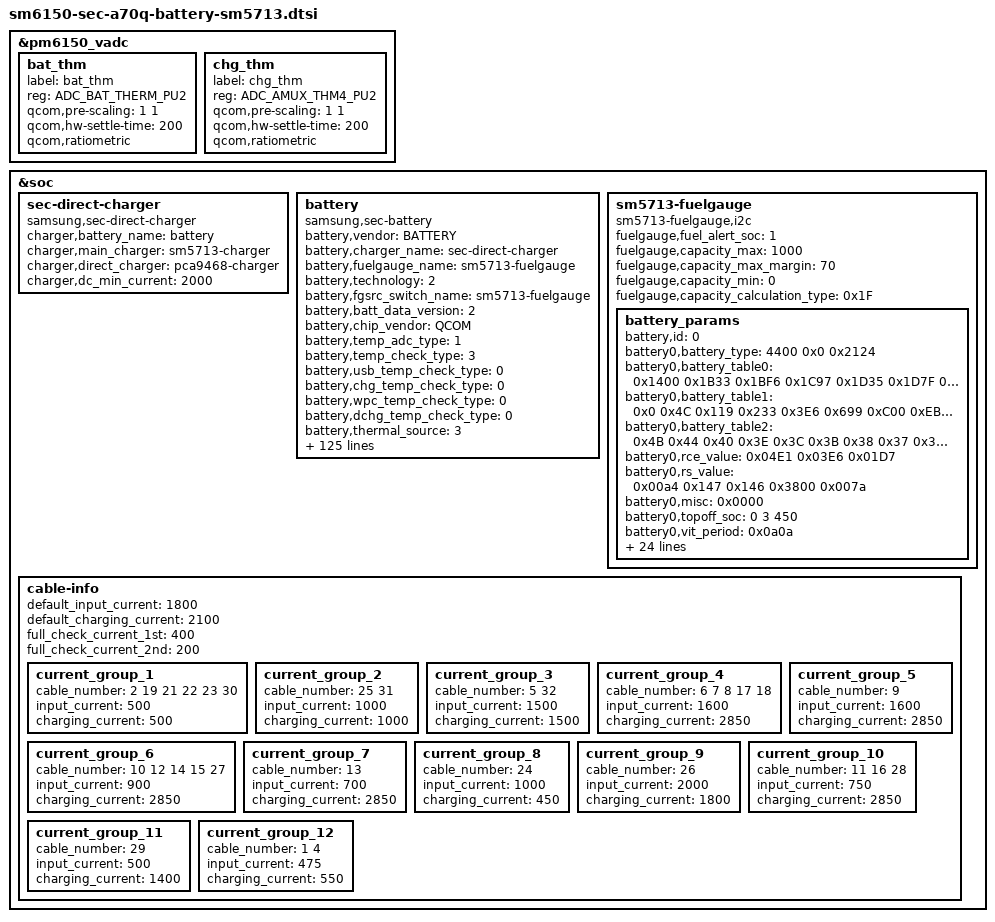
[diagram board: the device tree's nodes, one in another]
/* Copyright (c) 2014, The Linux Foundation. All rights reserved.
 *
 * This program is free software; you can redistribute it and/or modify
 * it under the terms of the GNU General Public License version 2 and
 * only version 2 as published by the Free Software Foundation.
 *
 * This program is distributed in the hope that it will be useful,
 * but WITHOUT ANY WARRANTY; without even the implied warranty of
 * MERCHANTABILITY or FITNESS FOR A PARTICULAR PURPOSE.  See the
 * GNU General Public License for more details.
 */

&pm6150_vadc {
	bat_thm { /* BAT_THERM */
		label = "bat_thm";
		reg = <ADC_BAT_THERM_PU2>;
		qcom,pre-scaling = <1 1>;
		qcom,hw-settle-time = <200>;
		qcom,ratiometric;
	};
	chg_thm { /* AMUX_4 */
		label = "chg_thm";
		reg = <ADC_AMUX_THM4_PU2>;
		qcom,pre-scaling = <1 1>;
		qcom,hw-settle-time = <200>;
		qcom,ratiometric;
	};
};

&soc {
	sec-direct-charger {
		status = "okay";
		compatible = "samsung,sec-direct-charger";

		charger,battery_name = "battery";
		charger,main_charger = "sm5713-charger";
		charger,direct_charger = "pca9468-charger";

		charger,dc_min_current = <2000>;
	};

	battery {
		status = "okay";
		compatible = "samsung,sec-battery";
		pinctrl-names = "default";
		battery,vendor = "BATTERY";
		battery,charger_name = "sec-direct-charger";
		battery,fuelgauge_name = "sm5713-fuelgauge";
		battery,technology = <2>; /* POWER_SUPPLY_TECHNOLOGY_LION */
		battery,fgsrc_switch_name = "sm5713-fuelgauge"; /* Fuelgauge voltage source */

		battery,batt_data_version = <2>;

		battery,chip_vendor = "QCOM";
		battery,temp_adc_type = <1>; /* SEC_BATTERY_ADC_TYPE_AP */

		battery,temp_check_type = <3>; /* SEC_BATTERY_TEMP_CHECK_ADC */
		battery,usb_temp_check_type = <0>;
		battery,chg_temp_check_type = <0>;
		battery,wpc_temp_check_type = <0>;
		battery,dchg_temp_check_type = <0>; /* SEC_BATTERY_TEMP_CHECK_NONE for test */

		battery,thermal_source = <3>; /* SEC_BATTERY_THERMAL_SOURCE_ADC */
		battery,usb_thermal_source = <0>; /* SEC_BATTERY_THERMAL_SOURCE_NONE */
		battery,chg_thermal_source = <3>; /* SEC_BATTERY_THERMAL_SOURCE_ADC */
		battery,wpc_thermal_source = <0>; /* SEC_BATTERY_THERMAL_SOURCE_NONE */
		battery,dchg_thermal_source = <3>; /* SEC_BATTERY_THERMAL_SOURCE_CHG_ADC */

		battery,polling_time = <10 30 30 30 3600>;

		battery,temp_table_adc = <121128 144571 172663 209017 245998
						291586 341283 402659 472728 547188
						629714 693750 796993 896626 1005211
						1117430 1217992 1321993 1417603 1502075
						1573766 1637781 1684580>;
		battery,temp_table_data = <900 850 800 750 700
						650 600 550 500 450
						400 350 300 250 200
						150 100 50 0 (-50)
						(-100) (-150) (-200)>;

		battery,chg_temp_table_adc = <118209 142495 170328 206617 244204
						289727 339532 401340 471755 547123
						627421 691586 794744 894246 1003135
						1115419 1215484 1319225 1415419 1499740
						1569095 1638126 1685639>;
		battery,chg_temp_table_data = <900 850 800 750 700
						650 600 550 500 450
						400 350 300 250 200
						150 100 50 0 (-50)
						(-100) (-150) (-200)>;

		battery,dchg_temp_table_adc = <110882 138414 166566 194718 234600
						276828 326094 387090 448086 525504
						607614 696762 792948 893826 999396
						1107312 1210536 1304376 1393524 1473288
						1543668 1602318 1651584>;
		battery,dchg_temp_table_data = <900 850 800 750 700
						650 600 550 500 450
						400 350 300 250 200
						150 100 50 0 (-50)
						(-100) (-150) (-200)>;

		battery,adc_check_count = <5>;

		battery,cable_check_type = <4>; /* SEC_BATTERY_CABLE_CHECK_PSY */
		battery,cable_source_type = <1>; /* SEC_BATTERY_CABLE_SOURCE_EXTERNAL */
		battery,polling_type = <1>; /* SEC_BATTERY_MONITOR_ALARM */
		battery,monitor_initial_count = <0>;

		battery,battery_check_type = <0>; /* SEC_BATTERY_CHECK_NONE */
		battery,check_count = <0>;
		battery,check_adc_max = <1440>;
		battery,check_adc_min = <0>;

		battery,ovp_uvlo_check_type = <3>; /* SEC_BATTERY_OVP_UVLO_CHGPOLLING */

		battery,temp_check_count = <1>;
		battery,temp_highlimit_threshold_event = <800>;
		battery,temp_highlimit_recovery_event = <750>;
		battery,temp_high_threshold_event = <500>;
		battery,temp_high_recovery_event = <450>;
		battery,temp_low_threshold_event = <0>;
		battery,temp_low_recovery_event = <50>;
		battery,temp_highlimit_threshold_normal = <800>;
		battery,temp_highlimit_recovery_normal = <750>;
		battery,temp_high_threshold_normal = <500>;
		battery,temp_high_recovery_normal = <450>;
		battery,temp_low_threshold_normal = <0>;
		battery,temp_low_recovery_normal = <50>;
		battery,temp_highlimit_threshold_lpm = <800>;
		battery,temp_highlimit_recovery_lpm = <750>;
		battery,temp_high_threshold_lpm = <500>;
		battery,temp_high_recovery_lpm = <450>;
		battery,temp_low_threshold_lpm = <0>;
		battery,temp_low_recovery_lpm = <50>;
		
		battery,full_check_type = <2>; /* SEC_BATTERY_FULLCHARGED_FG_CURRENT */
		battery,full_check_type_2nd = <2>; /* SEC_BATTERY_FULLCHARGED_FG_CURRENT */
		battery,full_check_count = <1>;
		battery,chg_gpio_full_check = <0>;
		battery,chg_polarity_full_check = <1>;

		battery,chg_high_temp = <460>;
		battery,chg_high_temp_recovery = <440>;
		battery,chg_input_limit_current = <1000>;
		battery,chg_charging_limit_current = <1250>;
		battery,dchg_input_limit_current = <1000>;
		battery,dchg_charging_limit_current = <2000>;

		battery,mix_high_temp = <420>;
		battery,mix_high_chg_temp = <500>;
		battery,mix_high_temp_recovery = <390>;

		/* SEC_BATTERY_FULL_CONDITION_NOTIMEFULL | SEC_BATTERY_FULL_CONDITION_VCELL */
		battery,full_condition_type = <9>;
		battery,full_condition_soc = <93>;
		battery,full_condition_vcell = <4250>;

		battery,recharge_check_count = <1>;
		battery,recharge_condition_type = <4>; /* SEC_BATTERY_RECHARGE_CONDITION_VCELL */
		battery,recharge_condition_soc = <98>;
		battery,recharge_condition_vcell = <4280>;

		battery,charging_total_time = <14400>;
		battery,hv_charging_total_time = <10800>;
		battery,normal_charging_total_time = <18000>;
		battery,usb_charging_total_time = <36000>;
		battery,recharging_total_time = <5400>;
		battery,charging_reset_time = <0>;

		battery,chg_float_voltage = <4350>;

		battery,pre_afc_work_delay = <2000>;
		battery,pre_wc_afc_work_delay = <4000>;
		battery,pre_afc_input_current = <500>;
		battery,pre_wc_afc_input_current = <500>;
		battery,prepare_ta_delay = <0>; /* msec */

		battery,swelling_high_temp_block = <410>;
		battery,swelling_high_temp_recov = <390>;
		battery,swelling_low_temp_block_1st = <150>;
		battery,swelling_low_temp_recov_1st = <200>;
		battery,swelling_low_temp_block_2nd = <50>;
		battery,swelling_low_temp_recov_2nd = <100>;

		battery,swelling_low_temp_current = <950>;	/* 0.3C */
		battery,swelling_low_temp_current_2nd = <400>;	/* 0.1C */
		battery,swelling_low_temp_topoff = <200>;	/* 0.05C */
		battery,swelling_high_temp_current = <1400>;	/* 0.45C */
		battery,swelling_high_temp_topoff = <200>;	/* 0.05C */
		battery,swelling_wc_high_temp_current = <1400>;	/* 0.3C */
		battery,swelling_wc_low_temp_current = <950>;	/* 0.3C */
		battery,swelling_wc_low_temp_current_2nd = <400>;	/* 0.1C */

		battery,swelling_drop_float_voltage = <4150>;
		battery,swelling_high_rechg_voltage = <4000>;
		battery,swelling_low_rechg_voltage = <4000>;

		battery,siop_event_check_type = <1>;
		battery,siop_call_cv_current = <330>;
		battery,siop_call_cc_current = <330>;

		battery,siop_input_limit_current = <1200>;
		battery,siop_charging_limit_current = <1000>;
		battery,siop_hv_input_limit_current = <500>;
		battery,siop_hv_charging_limit_current = <1000>;

		battery,pd_charging_charge_power = <25000>;
		battery,max_charging_current = <5100>;

		/* cycle, chg_float_voltage, recharge_condition_vcell, full_condition_vcell, full_condition_soc */
		battery,age_data = <0 4350 4280 4250 93
				300 4330 4260 4230 92
				400 4310 4240 4210 91
				700 4290 4220 4190 90
				1000 4240 4170 4140 89>;

		/* step charging option */
		battery,step_charging_type = <0x61>; /* STEP_CHARGING_CONDITION_INPUT_CURRENT, CURRENT_NOW, FLOAT_VOLTAGE, VOLTAGE */
		battery,step_charging_charge_power = <15000>;
		battery,step_charging_condtion = <2000 1570 0>;
		battery,step_charging_soc_condtion = <40 70 100>;
		battery,step_charging_current = <4500 3950 3150>;
		battery,step_charging_float_voltage = <4090 4220 4350>;

		battery,max_input_voltage = <9000>; /* mV */
		battery,max_input_current = <3000>;  /* mA */

		battery,enable_sysovlo_irq;

		battery,standard_curr = <2850>;
		battery,expired_time = <10800>;
		battery,recharging_expired_time = <5400>;

		battery,battery_full_capacity = <4000>;
		battery,cisd_max_voltage_thr = <4400>; /* batttery ovp dettection voltage */
		battery,cisd_alg_index = <7>;

		io-channels = <&pm6150_vadc ADC_BAT_THERM_PU2>, <&pm6150_vadc ADC_AMUX_THM4_PU2>;
		io-channel-names = "adc-temp", "adc-chg-temp";
	};

	sm5713-fuelgauge{
			status = "okay";
			compatible = "sm5713-fuelgauge,i2c";
			fuelgauge,fuel_alert_soc = <1>;
			fuelgauge,capacity_max = <1000>;
			fuelgauge,capacity_max_margin = <70>;
			fuelgauge,capacity_min = <0>;
			fuelgauge,capacity_calculation_type = <0x1F>;
			battery_params {
				battery,id = <0>;
				battery0,battery_type = <4400 0x0 0x2124>; /* 4200 or 4350 or 4400 */
				battery0,battery_table0 = <0x1400 0x1B33 0x1BF6 0x1C97 0x1D35 0x1D7F 0x1D92 0x1DBA 0x1DF2 0x1E38 0x1E68 0x1EA0 0x1ED6 0x1F03 0x1F49 0x1F71 0x1FB7 0x1FC6 0x1FE9 0x202D 0x2086 0x20D1 0x2209 0x2400>;
				battery0,battery_table1 = <0x0 0x4C 0x119 0x233 0x3E6 0x699 0xC00 0xEB3 0x1433 0x1F00 0x29E6 0x3200 0x3780 0x3A33 0x3CE6 0x3F99 0x4500 0x47CC 0x4A80 0x4D33 0x4FE6 0x554C 0x6400 0x6419>;
				battery0,battery_table2 = <0x4B 0x44 0x40 0x3E 0x3C 0x3B 0x38 0x37 0x35 0x34 0x34 0x33 0x33 0x33 0x33 0x32>;
				battery0,rce_value = <0x04E1 0x03E6 0x01D7>;
				battery0,rs_value = <0x00a4 0x147 0x146 0x3800 0x007a>; /*rs p_mix_factor, n_mix_factor max min*/
				battery0,misc = <0x0000>;
				battery0,topoff_soc = <0 3 450>; /*disable soc*/
				battery0,vit_period = <0x0a0a>;
				battery0,dtcd_value = <0x1>;
				battery0,volt_cal = <0x800b 0x800b>;
				battery0,curr_offset = <1 0 0 0 0 0 0>;
				battery0,mix_value = <0x0103 0x0004>; /*mix_rate init_blank*/
				battery0,temp_std = <25>;
				battery0,temp_cal = <0 6 1 11 (-1) 1 6 1 9 1>;
				battery0,ext_temp_cal = <0 2 1 2 1 1 2 3 2 3>;
				battery0,temp_volcal = <1 15 1>;
				battery0,temp_offset = <1 11 1 1 8 (-1)>;
				battery0,curr_cal = <0x8080 0x8080 0x8080 0x8080 0x8080 0x8080>;
				battery0,tem_poff = <3400 50 3250 50>;
				battery0,arsm = <1 3 1 0x6>;
				battery0,cycle_cfg = <0 0 0>;
				battery0,full_offset = <0 50 0 0xD1 0x90>;
				battery0,age_cntl = <0x325>;
				battery0,tcal_ioff = <0x02 0x00>;
				battery0,v_offset_cancel = <0 0 100 10>;
				battery0,v_alarm = <3100 0>;
				battery0,v_max_table = <0x2209 0x2200 0x21ED 0x21CB 0x2175>;
				battery0,q_max_table = <0x2124 0x1CC4 0x1C44 0x1BC4 0x1A85>;
				battery0,data_ver = <1>;
			};
		};

/* sec_battery_cable
 *   0	UNKNOWN,
 *   1	NONE,
 *   2	PREPARE_TA,
 *   3	TA,
 *   4	USB,
 *   5	USB_CDP,
 *   6	9V_TA,
 *   7	9V_ERR,
 *   8	9V_UNKNOWN,
 *   9	12V_TA,
 *  10	WIRELESS,
 *  11	HV_WIRELESS,
 *  12	PMA_WIRELESS,
 *  13	WIRELESS_PACK,
 *  14	WIRELESS_PACK_TA,
 *  15	WIRELESS_STAND,
 *  16	WIRELESS_HV_STAND,
 *  17	QC20,
 *  18	QC30,
 *  19	PDIC,
 *  20	UARTOFF,
 *  21	OTG,
 *  22	LAN_HUB,
 *  23	POWER_SHARING,
 *  24	HMT_CONNECTED,
 *  25	HMT_CHARGE,
 *  26	HV_TA_CHG_LIMIT,
 *  27	WIRELESS_VEHICLE,
 *  28	WIRELESS_HV_VEHICLE,
 *  29	PREPARE_WIRELESS_HV,
 *  30	TIMEOUT,
 *  31	SMART_OTG,
 *  32	SMART_NOTG,
 *  33	PDIC_PPS,
 *  34	CABLE_MAX,
*/
	cable-info {
		default_input_current = <1800>;
		default_charging_current = <2100>;
		full_check_current_1st = <400>;
		full_check_current_2nd = <200>;

		current_group_1 {
			cable_number = <2 19 21 22 23 30>;
			input_current = <500>;
			charging_current = <500>;
		};
		current_group_2 {
			cable_number = <25 31>;
			input_current = <1000>;
			charging_current = <1000>;
		};
		current_group_3 {
			cable_number = <5 32>;
			input_current = <1500>;
			charging_current = <1500>;
		};
		current_group_4 {
			cable_number = <6 7 8 17 18>;
			input_current = <1600>;
			charging_current = <2850>;
		};
		current_group_5 {
			cable_number = <9>;
			input_current = <1600>;
			charging_current = <2850>;
		};
		current_group_6 {
			cable_number = <10 12 14 15 27>;
			input_current = <900>;
			charging_current = <2850>;
		};
		current_group_7 {
			cable_number = <13>;
			input_current = <700>;
			charging_current = <2850>;
		};
		current_group_8 {
			cable_number = <24>;
			input_current = <1000>;
			charging_current = <450>;
		};
		current_group_9 {
			cable_number = <26>;
			input_current = <2000>;
			charging_current = <1800>;
		};
		current_group_10 {
			cable_number = <11 16 28>;
			input_current = <750>;
			charging_current = <2850>;
		};
		current_group_11 {
			cable_number = <29>;
			input_current = <500>;
			charging_current = <1400>;
		};
		current_group_12 {
			cable_number = <1 4>;
			input_current = <475>;
			charging_current = <550>;
		};
	};
};
